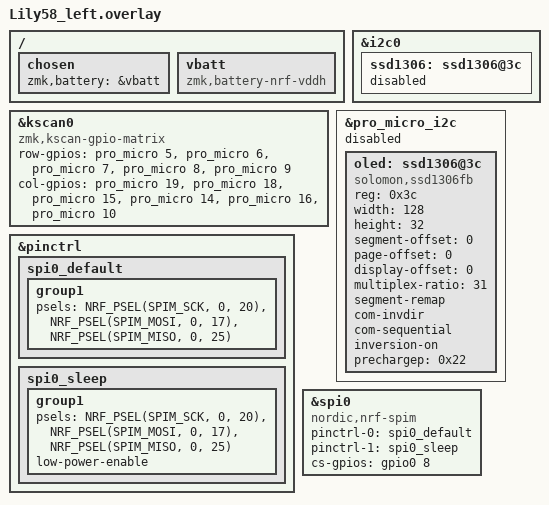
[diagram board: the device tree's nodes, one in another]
#include "Lily58.dtsi"

&kscan0 {
    compatible = "zmk,kscan-gpio-matrix";
    row-gpios
        = <&pro_micro 5 (GPIO_ACTIVE_HIGH | GPIO_PULL_DOWN)>
        , <&pro_micro 6 (GPIO_ACTIVE_HIGH | GPIO_PULL_DOWN)>
        , <&pro_micro 7 (GPIO_ACTIVE_HIGH | GPIO_PULL_DOWN)>
        , <&pro_micro 8 (GPIO_ACTIVE_HIGH | GPIO_PULL_DOWN)>
        , <&pro_micro 9 (GPIO_ACTIVE_HIGH | GPIO_PULL_DOWN)>
        ;
    col-gpios
        = <&pro_micro 19 GPIO_ACTIVE_HIGH>
        , <&pro_micro 18 GPIO_ACTIVE_HIGH>
        , <&pro_micro 15 GPIO_ACTIVE_HIGH>
        , <&pro_micro 14 GPIO_ACTIVE_HIGH>
        , <&pro_micro 16 GPIO_ACTIVE_HIGH>
        , <&pro_micro 10 GPIO_ACTIVE_HIGH>
        ;
};

/ {
    chosen {
        zmk,battery = &vbatt;
    };

    vbatt: vbatt {
        compatible = "zmk,battery-nrf-vddh";
    };
};

&i2c0 {  
    ssd1306: ssd1306@3c {  
        status = "disabled";
    };  
};

&pro_micro_i2c {
    status = "disabled";

    oled: ssd1306@3c {
        compatible = "solomon,ssd1306fb";
        reg = <0x3c>;
        width = <128>;
        height = <32>;
        segment-offset = <0>;
        page-offset = <0>;
        display-offset = <0>;
        multiplex-ratio = <31>;
        segment-remap;
        com-invdir;
        com-sequential;
        inversion-on;
        prechargep = <0x22>;
    };
};

&pinctrl {
    spi0_default: spi0_default {
        group1 {
            psels = <NRF_PSEL(SPIM_SCK, 0, 20)>,
                <NRF_PSEL(SPIM_MOSI, 0, 17)>,
                <NRF_PSEL(SPIM_MISO, 0, 25)>;
        };
    };
    spi0_sleep: spi0_sleep {
        group1 {
            psels = <NRF_PSEL(SPIM_SCK, 0, 20)>,
                <NRF_PSEL(SPIM_MOSI, 0, 17)>,
                <NRF_PSEL(SPIM_MISO, 0, 25)>;
            low-power-enable;
        };
    };
};

nice_view_spi: &spi0 {
    compatible = "nordic,nrf-spim";
    pinctrl-0 = <&spi0_default>;
    pinctrl-1 = <&spi0_sleep>;
    pinctrl-names = "default", "sleep";
    cs-gpios = <&gpio0 8 GPIO_ACTIVE_HIGH>;
};
